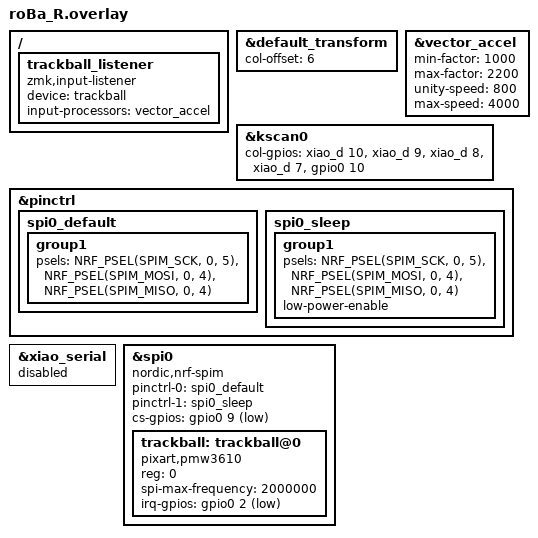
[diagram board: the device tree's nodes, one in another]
#include "roBa.dtsi"
#include <zmk-input-vector-acceleration/input_processor_vector_accel.dtsi>

&default_transform {
    col-offset = <6>;
};

// ポインタ加速の曲線。速度の単位はセンサーのカウント/秒 (CPI 600 なら 1000 カウント/秒 ≒ 指速 42mm/秒)。
//   - unity-speed 以下 : 倍率 1.0 (min-factor=1000 なので低速側は減速しない。CPI 600 そのまま)
//   - unity-speed〜max-speed : 二次曲線で 1.0 → max-factor
//       例) 1600 c/s ≒ 1.08倍, 2400 ≒ 1.3倍, 3200 ≒ 1.7倍, 4000 以上 = 2.2倍
// 加速を切りたいときは max-factor = <1000> にする
&vector_accel {
    min-factor = <1000>;
    max-factor = <2200>;
    unity-speed = <800>;
    max-speed = <4000>;
};

&kscan0 {
        col-gpios
            = <&xiao_d 10 GPIO_ACTIVE_HIGH>
            , <&xiao_d 9 GPIO_ACTIVE_HIGH>
            , <&xiao_d 8 GPIO_ACTIVE_HIGH>
            , <&xiao_d 7 GPIO_ACTIVE_HIGH>
            , <&gpio0 10 GPIO_ACTIVE_HIGH>
            ;
};

/ {
    trackball_listener {
        status = "okay";
        compatible = "zmk,input-listener";
        device = <&trackball>;
        // トラックボールの相対移動 (REL_X/REL_Y) にのみ加速を掛ける。
        // scroll-layers でドライバが出すホイールイベントは素通し
        input-processors = <&vector_accel>;
    };
};

&pinctrl {
    spi0_default: spi0_default {
        group1 {
            psels = <NRF_PSEL(SPIM_SCK, 0, 5)>,
                <NRF_PSEL(SPIM_MOSI, 0, 4)>,
                <NRF_PSEL(SPIM_MISO, 0, 4)>;
        };
    };

    spi0_sleep: spi0_sleep {
        group1 {
            psels = <NRF_PSEL(SPIM_SCK, 0, 5)>,
                <NRF_PSEL(SPIM_MOSI, 0, 4)>,
                <NRF_PSEL(SPIM_MISO, 0, 4)>;
            low-power-enable;
        };
    };
};

&xiao_serial { status = "disabled"; };

&spi0 {
    status = "okay";
    compatible = "nordic,nrf-spim";
    pinctrl-0 = <&spi0_default>;
    pinctrl-1 = <&spi0_sleep>;
    pinctrl-names = "default", "sleep";
    cs-gpios = <&gpio0 9 GPIO_ACTIVE_LOW>;

    trackball: trackball@0 {
        status = "okay";
        compatible = "pixart,pmw3610";
        reg = <0>;
        spi-max-frequency = <2000000>;
        irq-gpios = <&gpio0 2 (GPIO_ACTIVE_LOW | GPIO_PULL_UP)>;
    };
};
